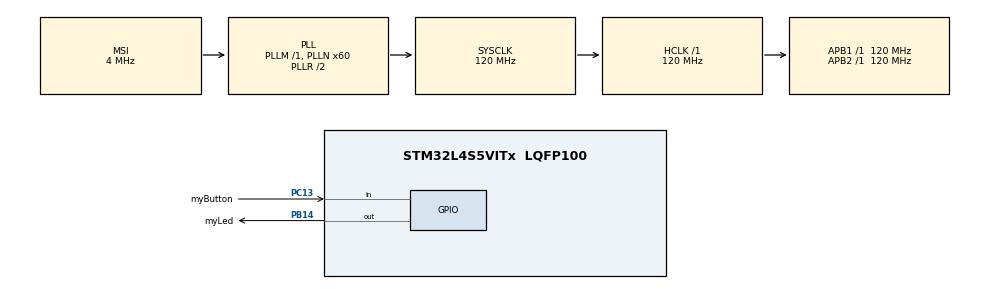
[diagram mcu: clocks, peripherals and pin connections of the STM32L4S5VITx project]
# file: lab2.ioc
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ADC1.Channel-0\#ChannelRegularConversion=ADC_CHANNEL_TEMPSENSOR
ADC1.NbrOfConversionFlag=1
ADC1.OffsetNumber-0\#ChannelRegularConversion=ADC_OFFSET_NONE
ADC1.Rank-0\#ChannelRegularConversion=1
ADC1.SamplingTime-0\#ChannelRegularConversion=ADC_SAMPLETIME_640CYCLES_5
ADC1.master=1
Mcu.Family=STM32L4
Mcu.Name=STM32L4S5VITx
Mcu.Package=LQFP100
NVIC.PriorityGroup=NVIC_PRIORITYGROUP_4
PA13\ (JTMS/SWDIO).Signal=SYS_JTMS-SWDIO
PB14.GPIO_Label=myLed
PB14.Signal=GPIO_Output
PB3\ (JTDO/TRACESWO).Signal=SYS_JTDO-SWO
PC13.GPIO_Label=myButton
PC13.Signal=GPIO_Input
ProjectManager.HeapSize=0x200
ProjectManager.StackSize=0x400
ProjectManager.TargetToolchain=STM32CubeIDE
RCC.ADCFreq_Value=48000000
RCC.AHBFreq_Value=120000000
RCC.APB1Freq_Value=120000000
RCC.APB1TimFreq_Value=120000000
RCC.APB2Freq_Value=120000000
RCC.APB2TimFreq_Value=120000000
RCC.CortexFreq_Value=120000000
RCC.HCLKFreq_Value=120000000
RCC.HSE_VALUE=8000000
RCC.HSI48_VALUE=48000000
RCC.HSI_VALUE=16000000
RCC.LSE_VALUE=32768
RCC.MSI_VALUE=4000000
RCC.PLLN=60
RCC.PLLSAI1N=24
RCC.SYSCLKFreq_VALUE=120000000
RCC.SYSCLKSource=RCC_SYSCLKSOURCE_PLLCLK
RCC.USBFreq_Value=48000000
RCC.VCOOutputFreq_Value=240000000
VP_ADC1_TempSens_Input.Mode=IN-TempSens
VP_ADC1_Vref_Input.Mode=IN-Vrefint
board=B-L4S5I-IOT01A

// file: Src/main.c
/* USER CODE BEGIN Header */
/**
  ******************************************************************************
  * @file           : main.c
  * @brief          : Main program body
  ******************************************************************************
  * @attention
  *
  * Copyright (c) 2023 STMicroelectronics.
  * All rights reserved.
  *
  * This software is licensed under terms that can be found in the LICENSE file
  * in the root directory of this software component.
  * If no LICENSE file comes with this software, it is provided AS-IS.
  *
  ******************************************************************************
  */
/* USER CODE END Header */
#include "main.h"

/* USER CODE BEGIN Includes */
#include <math.h>
#include <stdio.h>
//#include "stm32l4xx_hal_adc_ex.h"

/* USER CODE END Includes */

ADC_HandleTypeDef hadc1;

void SystemClock_Config(void);
static void MX_GPIO_Init(void);
static void MX_ADC1_Init(void);
/* USER CODE BEGIN PFP */
void configure_channels(int i);

/* USER CODE END PFP */

/* USER CODE BEGIN 0 */

#define VREFINT ((uint16_t*)(uint32_t)0x1FFF75AA)
#define TS_CAL1 ((uint16_t*)(uint32_t)0x1FFF75A8) //TS ADC raw data acquired at a temperature of 30 °C  (AROUND 3 V)
#define TS_CAL2 ((uint16_t*)(uint32_t)0x1FFF75CA) //TS ADC raw data acquired at a temperature of 130 °C

#define TS_CAL1_TEMP ((float)30.0) //temp used to measure TS_CAL1
#define TS_CAL2_TEMP ((float) 130.0) //temp used to measure TS_CAL2

//conditional compiling

//#define LED_OF
#define LED_TOG

/* USER CODE END 0 */

int main(void)
{

  /* MCU Configuration--------------------------------------------------------*/

  /* Reset of all peripherals, Initializes the Flash interface and the Systick. */
  HAL_Init();

  /* Configure the system clock */
  SystemClock_Config();

  /* Initialize all configured peripherals */
  MX_GPIO_Init();
  MX_ADC1_Init();
  /* USER CODE BEGIN 2 */

//  while(HAL_ADCEx_Calibration_Start(&hadc1,0) != HAL_OK);           // calibrate AD convertor

//  HAL_ADCEx_CalibrationStart(); //improve accuarcy of ADC conversion by calibrating driver
  char status = 0;
  char error = 0;

  float temp;
  float vref;
  float vref_temp;

  /* USER CODE END 2 */

  /* Infinite loop */
  while (1)
  {

    /* USER CODE BEGIN 3 */

	//program to turn lED on/off
	#ifdef LED_OF
	status = HAL_GPIO_ReadPin(myButton_GPIO_Port, myButton_Pin); //check button status
	if (status == 0){
	  HAL_GPIO_WritePin(myLed_GPIO_Port, myLed_Pin, GPIO_PIN_SET); //turn LED on if button is 0
	  configure_channels(1); //temp
	}else{
	  HAL_GPIO_WritePin(myLed_GPIO_Port, myLed_Pin, GPIO_PIN_RESET); //turn off LED
	  configure_channels(0); //voltage
	}
	#endif

	//program to toggle LED
	//let LED off mode = voltage & LED ON => temperature

	#ifdef LED_TOG
	status = HAL_GPIO_ReadPin(myButton_GPIO_Port, myButton_Pin); //check button status
	if (status == 0){ //if button is on, toggle mode
		float current = HAL_GPIO_ReadPin(myLed_GPIO_Port, myLed_Pin); //get current LED value
		if (current == 0){  //if LED is currently off, toggle on
			HAL_GPIO_WritePin(myLed_GPIO_Port, myLed_Pin, GPIO_PIN_SET);
			printf("Turning on LED.\nMeasuring temperature now.\n");

		}else{ //if LED is currently on, toggle off
			HAL_GPIO_WritePin(myLed_GPIO_Port, myLed_Pin, GPIO_PIN_RESET);
			printf("Turning off LED. \nMeasuring voltage now.\n");
		}
	}
	#endif

	//measure voltage
	configure_channels(0); 										//switch to voltage channel on ADC MUX
	HAL_ADC_Start(&hadc1); 								   //activate peripheral and start conversion
	HAL_ADC_PollForConversion(&hadc1, HAL_MAX_DELAY);  	  //wait for completion
	float raw_voltage = HAL_ADC_GetValue(&hadc1);		  //read sensor's digital value
	HAL_ADC_Stop(&hadc1);
	vref = 3.0f * (*VREFINT)/raw_voltage;

	float current = HAL_GPIO_ReadPin(myLed_GPIO_Port, myLed_Pin); //get current LED value
	if (current == 0){ //if LED is off, measure voltage
		printf("voltage = %3.3fV\n", vref);                  // display chip's temperature (176 to display the degree sign)

	}else{ //otherwise measure temperature

		//TEMPERATURE
		configure_channels(1);									 //configure temperature MUX channel
		HAL_ADC_Start(&hadc1); 									//activate peripheral and start conversion
		HAL_ADC_PollForConversion(&hadc1, HAL_MAX_DELAY);  		//wait for completion
		float raw_temp = HAL_ADC_GetValue(&hadc1);				//read sensor's digital value
		HAL_ADC_Stop(&hadc1);
		float temp = ((100.0/(*TS_CAL2 - *TS_CAL1)) * ((raw_temp * (vref/3.0)) - *TS_CAL1)) + 30.0;
		printf("temp = %3.3f%cC\n", temp, 176);

	}

    HAL_Delay(1000); //wait 1000 ms

  }

  /* USER CODE END 3 */
}

void SystemClock_Config(void)
{
  RCC_OscInitTypeDef RCC_OscInitStruct = {0};
  RCC_ClkInitTypeDef RCC_ClkInitStruct = {0};

  /** Configure the main internal regulator output voltage
  */
  if (HAL_PWREx_ControlVoltageScaling(PWR_REGULATOR_VOLTAGE_SCALE1_BOOST) != HAL_OK)
  {
    Error_Handler();
  }

  /** Initializes the RCC Oscillators according to the specified parameters
  * in the RCC_OscInitTypeDef structure.
  */
  RCC_OscInitStruct.OscillatorType = RCC_OSCILLATORTYPE_MSI;
  RCC_OscInitStruct.MSIState = RCC_MSI_ON;
  RCC_OscInitStruct.MSICalibrationValue = 0;
  RCC_OscInitStruct.MSIClockRange = RCC_MSIRANGE_6;
  RCC_OscInitStruct.PLL.PLLState = RCC_PLL_ON;
  RCC_OscInitStruct.PLL.PLLSource = RCC_PLLSOURCE_MSI;
  RCC_OscInitStruct.PLL.PLLM = 1;
  RCC_OscInitStruct.PLL.PLLN = 60;
  RCC_OscInitStruct.PLL.PLLP = RCC_PLLP_DIV2;
  RCC_OscInitStruct.PLL.PLLQ = RCC_PLLQ_DIV2;
  RCC_OscInitStruct.PLL.PLLR = RCC_PLLR_DIV2;
  if (HAL_RCC_OscConfig(&RCC_OscInitStruct) != HAL_OK)
  {
    Error_Handler();
  }

  /** Initializes the CPU, AHB and APB buses clocks
  */
  RCC_ClkInitStruct.ClockType = RCC_CLOCKTYPE_HCLK|RCC_CLOCKTYPE_SYSCLK
                              |RCC_CLOCKTYPE_PCLK1|RCC_CLOCKTYPE_PCLK2;
  RCC_ClkInitStruct.SYSCLKSource = RCC_SYSCLKSOURCE_PLLCLK;
  RCC_ClkInitStruct.AHBCLKDivider = RCC_SYSCLK_DIV1;
  RCC_ClkInitStruct.APB1CLKDivider = RCC_HCLK_DIV1;
  RCC_ClkInitStruct.APB2CLKDivider = RCC_HCLK_DIV1;

  if (HAL_RCC_ClockConfig(&RCC_ClkInitStruct, FLASH_LATENCY_5) != HAL_OK)
  {
    Error_Handler();
  }
}

static void MX_ADC1_Init(void)
{

  ADC_ChannelConfTypeDef sConfig = {0};

  /** Common config
  */
  hadc1.Instance = ADC1;
  hadc1.Init.ClockPrescaler = ADC_CLOCK_ASYNC_DIV1;
  hadc1.Init.Resolution = ADC_RESOLUTION_12B;
  hadc1.Init.DataAlign = ADC_DATAALIGN_RIGHT;
  hadc1.Init.ScanConvMode = ADC_SCAN_DISABLE;
  hadc1.Init.EOCSelection = ADC_EOC_SINGLE_CONV;
  hadc1.Init.LowPowerAutoWait = DISABLE;
  hadc1.Init.ContinuousConvMode = DISABLE;
  hadc1.Init.NbrOfConversion = 1;
  hadc1.Init.DiscontinuousConvMode = DISABLE;
  hadc1.Init.ExternalTrigConv = ADC_SOFTWARE_START;
  hadc1.Init.ExternalTrigConvEdge = ADC_EXTERNALTRIGCONVEDGE_NONE;
  hadc1.Init.DMAContinuousRequests = DISABLE;
  hadc1.Init.Overrun = ADC_OVR_DATA_PRESERVED;
  hadc1.Init.OversamplingMode = DISABLE;
  hadc1.Init.DFSDMConfig = ADC_DFSDM_MODE_ENABLE;
  if (HAL_ADC_Init(&hadc1) != HAL_OK)
  {
    Error_Handler();
  }

  /** Configure Regular Channel
  */
  sConfig.Channel = ADC_CHANNEL_TEMPSENSOR;
  sConfig.Rank = ADC_REGULAR_RANK_1;
  sConfig.SamplingTime = ADC_SAMPLETIME_2CYCLES_5;
  sConfig.SingleDiff = ADC_SINGLE_ENDED;
  sConfig.OffsetNumber = ADC_OFFSET_NONE;
  sConfig.Offset = 0;
  if (HAL_ADC_ConfigChannel(&hadc1, &sConfig) != HAL_OK)
  {
    Error_Handler();
  }

}

static void MX_GPIO_Init(void)
{
  GPIO_InitTypeDef GPIO_InitStruct = {0};

  /* GPIO Ports Clock Enable */
  __HAL_RCC_GPIOC_CLK_ENABLE();
  __HAL_RCC_GPIOB_CLK_ENABLE();
  __HAL_RCC_GPIOA_CLK_ENABLE();

  /*Configure GPIO pin Output Level */
  HAL_GPIO_WritePin(myLed_GPIO_Port, myLed_Pin, GPIO_PIN_RESET);

  /*Configure GPIO pin : myButton_Pin */
  GPIO_InitStruct.Pin = myButton_Pin;
  GPIO_InitStruct.Mode = GPIO_MODE_INPUT;
  GPIO_InitStruct.Pull = GPIO_NOPULL;
  HAL_GPIO_Init(myButton_GPIO_Port, &GPIO_InitStruct);

  /*Configure GPIO pin : myLed_Pin */
  GPIO_InitStruct.Pin = myLed_Pin;
  GPIO_InitStruct.Mode = GPIO_MODE_OUTPUT_PP;
  GPIO_InitStruct.Pull = GPIO_NOPULL;
  GPIO_InitStruct.Speed = GPIO_SPEED_FREQ_LOW;
  HAL_GPIO_Init(myLed_GPIO_Port, &GPIO_InitStruct);

}

/* USER CODE BEGIN 4 */

//configure channels
//0 for Vref and 1 for temp
void configure_channels(int i){

	ADC_ChannelConfTypeDef sConfig = {0};
	if (i == 0){
		sConfig.Channel = ADC_CHANNEL_VREFINT;
	}else{
		sConfig.Channel = ADC_CHANNEL_TEMPSENSOR;
	}
	sConfig.Rank = ADC_REGULAR_RANK_1;
	sConfig.SamplingTime = ADC_SAMPLETIME_640CYCLES_5;
	sConfig.SingleDiff = ADC_SINGLE_ENDED;
	sConfig.OffsetNumber = ADC_OFFSET_NONE;
	sConfig.Offset = 0;
	if (HAL_ADC_ConfigChannel(&hadc1, &sConfig) != HAL_OK)
	{
	Error_Handler();
	}

}

//function for printing to console (swb port 0)
int _write(int file, char *ptr, int len)
{
  (void)file;
  int DataIdx;

  for (DataIdx = 0; DataIdx < len; DataIdx++)
  {
	  ITM_SendChar(*ptr++);
  }
  return len;
}

/* USER CODE END 4 */

void Error_Handler(void)
{
  __disable_irq();
  while (1)
  {
  }
}
